LIN_description_file;
LIN_protocol_version = "2.2";
LIN_language_version = "2.2";
LIN_speed = 19.2 kbps;

Nodes {
  Master: Gateway, 1 ms, 0 ms ;
  Slaves: SCMM ;
}

Signals {
  Seat_up: 1, 0, Gateway, SCMM ;
  Seat_down: 1, 0, Gateway, SCMM ;
  Seat_forward: 1, 0, Gateway, SCMM ;
  Seat_back: 1, 0, Gateway, SCMM ;
  Seatback_forward: 1, 0, Gateway, SCMM ;
  Seatback_back: 1, 0, Gateway, SCMM ;
  Head_up: 1, 0, Gateway, SCMM ;
  Head_down: 1, 0, Gateway, SCMM ;
  DriverID: 8, 0, Gateway, SCMM ;
  Vertical_Position: 4, 5, SCMM, Gateway ;
  Horizontal_Position: 4, 9, SCMM, Gateway ;
  Head_Position: 3, 2, SCMM, Gateway ;
  SeatBack_Position: 4, 2, SCMM, Gateway ;
  Lock_Status: 8, 0, Gateway ;
}

Frames {
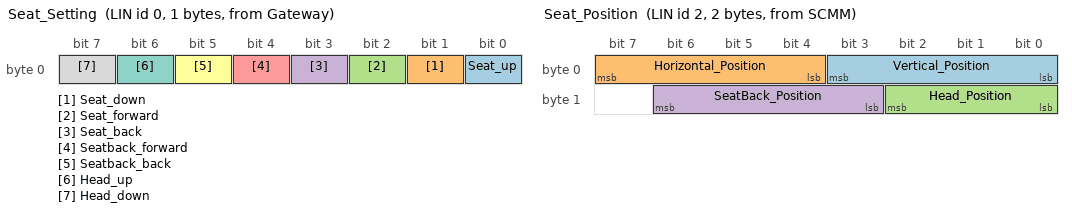
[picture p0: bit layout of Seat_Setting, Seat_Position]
  Seat_Setting: 0, Gateway, 1 {
    Seat_up, 0 ;
    Seat_down, 1 ;
    Seat_forward, 2 ;
    Seat_back, 3 ;
    Seatback_forward, 4 ;
    Seatback_back, 5 ;
    Head_up, 6 ;
    Head_down, 7 ;
  }
  Driver_Info: 1, Gateway, 1 {
    DriverID, 0 ;
  }
  Seat_Position: 2, SCMM, 2 {
    Vertical_Position, 0 ;
    Horizontal_Position, 4 ;
    Head_Position, 8 ;
    SeatBack_Position, 11 ;
  }
}

Node_attributes {
  SCMM{
    LIN_protocol = "2.2" ;
    configured_NAD = 0x1 ;
    initial_NAD = 0x1 ;
    product_id = 0x17, 0x1, 1 ;
    P2_min = 50 ms ;
    ST_min = 0 ms ;
    N_As_timeout = 1000 ms ;
    N_Cr_timeout = 1000 ms ;
    configurable_frames {
      Driver_Info ;
      Seat_Setting ;
      Seat_Position ;
    }
  }
}

Schedule_tables {
 Table_0 {
    Seat_Setting delay 30 ms ;
    Driver_Info delay 30 ms ;
    Seat_Position delay 30 ms ;
  }
}

Signal_encoding_types {
  Driver_Info_Encoding {
    physical_value, 0, 1, 1, 0 ;
  }
  Lock_Status_Encoding {
    physical_value, 0, 1, 1, 0 ;
  }
  Seat_Encoding {
    physical_value, 0, 1, 1, 0 ;
  }
  Seat_Position_Encoding {
    physical_value, 0, 10, 1, 0 ;
  }
}

Signal_representation {
  Driver_Info_Encoding: DriverID ;
  Lock_Status_Encoding: Lock_Status ;
  Seat_Encoding: Seat_up, Seat_down, Seat_forward, Seat_back, Seatback_forward, Seatback_back, Head_up, Head_down ;
  Seat_Position_Encoding: Vertical_Position, Horizontal_Position, Head_Position, SeatBack_Position ;
}
